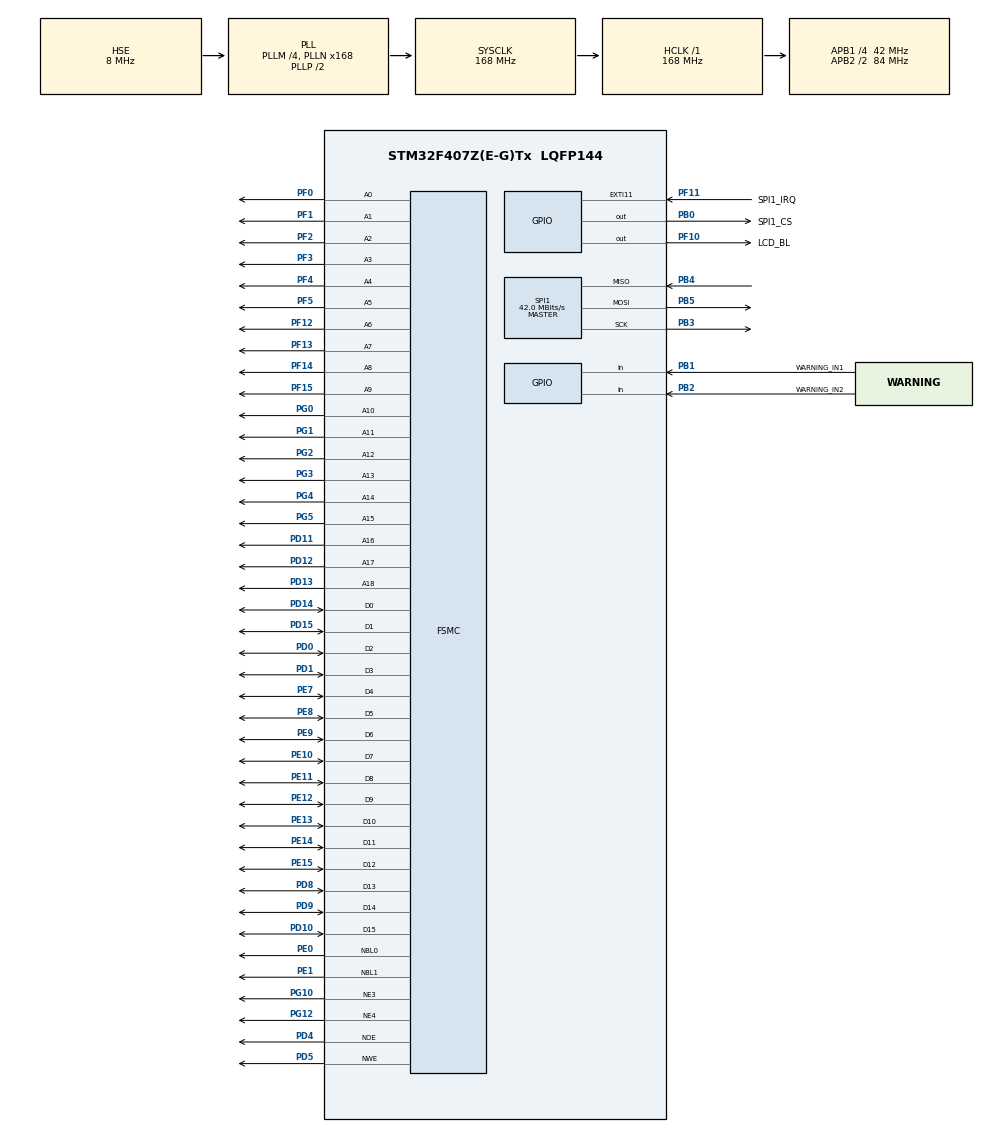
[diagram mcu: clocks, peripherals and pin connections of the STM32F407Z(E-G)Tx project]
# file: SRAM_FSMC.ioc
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Dma.Request0=SPI1_RX
Dma.Request1=SPI1_TX
Dma.SPI1_RX.0.Direction=DMA_PERIPH_TO_MEMORY
Dma.SPI1_RX.0.FIFOMode=DMA_FIFOMODE_DISABLE
Dma.SPI1_RX.0.Instance=DMA2_Stream0
Dma.SPI1_RX.0.MemDataAlignment=DMA_MDATAALIGN_HALFWORD
Dma.SPI1_RX.0.MemInc=DMA_MINC_ENABLE
Dma.SPI1_RX.0.Mode=DMA_NORMAL
Dma.SPI1_RX.0.PeriphDataAlignment=DMA_PDATAALIGN_HALFWORD
Dma.SPI1_RX.0.PeriphInc=DMA_PINC_DISABLE
Dma.SPI1_RX.0.Priority=DMA_PRIORITY_VERY_HIGH
Dma.SPI1_TX.1.Direction=DMA_MEMORY_TO_PERIPH
Dma.SPI1_TX.1.FIFOMode=DMA_FIFOMODE_DISABLE
Dma.SPI1_TX.1.Instance=DMA2_Stream3
Dma.SPI1_TX.1.MemDataAlignment=DMA_MDATAALIGN_HALFWORD
Dma.SPI1_TX.1.MemInc=DMA_MINC_ENABLE
Dma.SPI1_TX.1.Mode=DMA_NORMAL
Dma.SPI1_TX.1.PeriphDataAlignment=DMA_PDATAALIGN_HALFWORD
Dma.SPI1_TX.1.PeriphInc=DMA_PINC_DISABLE
Dma.SPI1_TX.1.Priority=DMA_PRIORITY_VERY_HIGH
FSMC.BusTurnAroundDuration2=15
FSMC.ExtendedMode1=FSMC_EXTENDED_MODE_ENABLE
FSMC.ExtendedMode2=FSMC_EXTENDED_MODE_ENABLE
FSMC.WriteOperation1=FSMC_WRITE_OPERATION_ENABLE
Mcu.Family=STM32F4
Mcu.Name=STM32F407Z(E-G)Tx
Mcu.Package=LQFP144
NVIC.DMA2_Stream0_IRQn=true\:0\:0\:false\:false\:true\:false\:true\:true
NVIC.DMA2_Stream3_IRQn=true\:0\:0\:false\:false\:true\:false\:true\:true
NVIC.EXTI15_10_IRQn=true\:0\:0\:false\:false\:true\:true\:true\:true
NVIC.PriorityGroup=NVIC_PRIORITYGROUP_4
NVIC.SPI1_IRQn=true\:0\:0\:false\:false\:true\:true\:true\:true
NVIC.TIM5_IRQn=true\:0\:0\:false\:false\:true\:true\:true\:true
PA13.Mode=Serial_Wire
PA13.Signal=SYS_JTMS-SWDIO
PA14.Mode=Serial_Wire
PA14.Signal=SYS_JTCK-SWCLK
PB0.GPIO_Label=SPI1_CS
PB0.GPIO_PuPd=GPIO_PULLUP
PB0.PinState=GPIO_PIN_SET
PB0.Signal=GPIO_Output
PB1.GPIO_Label=WARNING_IN1
PB1.Signal=GPIO_Input
PB2.GPIO_Label=WARNING_IN2
PB2.Signal=GPIO_Input
PB3.Mode=Full_Duplex_Master
PB3.Signal=SPI1_SCK
PB4.Mode=Full_Duplex_Master
PB4.Signal=SPI1_MISO
PB5.Mode=Full_Duplex_Master
PB5.Signal=SPI1_MOSI
PD0.GPIO_PuPd=GPIO_PULLDOWN
PD0.Signal=FSMC_D2_DA2
PD1.GPIO_PuPd=GPIO_PULLDOWN
PD1.Signal=FSMC_D3_DA3
PD10.GPIO_PuPd=GPIO_PULLDOWN
PD10.Signal=FSMC_D15_DA15
PD11.Signal=FSMC_A16_CLE
PD12.Signal=FSMC_A17_ALE
PD13.Signal=FSMC_A18
PD14.GPIO_PuPd=GPIO_PULLDOWN
PD14.Signal=FSMC_D0_DA0
PD15.GPIO_PuPd=GPIO_PULLDOWN
PD15.Signal=FSMC_D1_DA1
PD4.GPIO_PuPd=GPIO_PULLUP
PD4.Signal=FSMC_NOE
PD5.GPIO_PuPd=GPIO_PULLUP
PD5.Signal=FSMC_NWE
PD8.GPIO_PuPd=GPIO_PULLDOWN
PD8.Signal=FSMC_D13_DA13
PD9.GPIO_PuPd=GPIO_PULLDOWN
PD9.Signal=FSMC_D14_DA14
PE0.Signal=FSMC_NBL0
PE1.Signal=FSMC_NBL1
PE10.GPIO_PuPd=GPIO_PULLDOWN
PE10.Signal=FSMC_D7_DA7
PE11.GPIO_PuPd=GPIO_PULLDOWN
PE11.Signal=FSMC_D8_DA8
PE12.GPIO_PuPd=GPIO_PULLDOWN
PE12.Signal=FSMC_D9_DA9
PE13.GPIO_PuPd=GPIO_PULLDOWN
PE13.Signal=FSMC_D10_DA10
PE14.GPIO_PuPd=GPIO_PULLDOWN
PE14.Signal=FSMC_D11_DA11
PE15.GPIO_PuPd=GPIO_PULLDOWN
PE15.Signal=FSMC_D12_DA12
PE7.GPIO_PuPd=GPIO_PULLDOWN
PE7.Signal=FSMC_D4_DA4
PE8.GPIO_PuPd=GPIO_PULLDOWN
PE8.Signal=FSMC_D5_DA5
PE9.GPIO_PuPd=GPIO_PULLDOWN
PE9.Signal=FSMC_D6_DA6
PF0.Signal=FSMC_A0
PF1.Signal=FSMC_A1
PF10.GPIO_Label=LCD_BL
PF10.GPIO_PuPd=GPIO_PULLDOWN
PF10.Signal=GPIO_Output
PF11.GPIO_Label=SPI1_IRQ
PF11.GPIO_ModeDefaultEXTI=GPIO_MODE_IT_RISING_FALLING
PF11.GPIO_PuPd=GPIO_PULLUP
PF11.Signal=GPXTI11
PF12.Signal=FSMC_A6
PF13.Signal=FSMC_A7
PF14.Signal=FSMC_A8
PF15.Signal=FSMC_A9
PF2.Signal=FSMC_A2
PF3.Signal=FSMC_A3
PF4.Signal=FSMC_A4
PF5.Signal=FSMC_A5
PG0.Signal=FSMC_A10
PG1.Signal=FSMC_A11
PG10.Mode=NorPsramChipSelect3_1
PG10.Signal=FSMC_NE3
PG12.Mode=NorPsramChipSelect4_2
PG12.Signal=FSMC_NE4
PG2.Signal=FSMC_A12
PG3.Signal=FSMC_A13
PG4.Signal=FSMC_A14
PG5.Signal=FSMC_A15
PH0-OSC_IN.Mode=HSE-External-Oscillator
PH0-OSC_IN.Signal=RCC_OSC_IN
PH1-OSC_OUT.Mode=HSE-External-Oscillator
PH1-OSC_OUT.Signal=RCC_OSC_OUT
ProjectManager.HeapSize=0x200
ProjectManager.StackSize=0x400
ProjectManager.TargetToolchain=MDK-ARM V5
RCC.48MHZClocksFreq_Value=48000000
RCC.AHBFreq_Value=168000000
RCC.APB1CLKDivider=RCC_HCLK_DIV4
RCC.APB1Freq_Value=42000000
RCC.APB1TimFreq_Value=84000000
RCC.APB2CLKDivider=RCC_HCLK_DIV2
RCC.APB2Freq_Value=84000000
RCC.APB2TimFreq_Value=168000000
RCC.CortexFreq_Value=168000000
RCC.EnbaleCSS=true
RCC.HCLKFreq_Value=168000000
RCC.HSE_VALUE=8000000
RCC.HSI_VALUE=16000000
RCC.LSE_VALUE=32768
RCC.PLLM=4
RCC.PLLN=168
RCC.PLLQ=7
RCC.PLLSourceVirtual=RCC_PLLSOURCE_HSE
RCC.SYSCLKFreq_VALUE=168000000
RCC.SYSCLKSource=RCC_SYSCLKSOURCE_PLLCLK
RCC.VCOOutputFreq_Value=336000000
SH.FSMC_A0.0=FSMC_A0,19b-a1
SH.FSMC_A1.0=FSMC_A1,19b-a1
SH.FSMC_A10.0=FSMC_A10,19b-a1
SH.FSMC_A11.0=FSMC_A11,19b-a1
SH.FSMC_A12.0=FSMC_A12,A12_2
SH.FSMC_A12.1=FSMC_A12,19b-a1
SH.FSMC_A13.0=FSMC_A13,19b-a1
SH.FSMC_A14.0=FSMC_A14,19b-a1
SH.FSMC_A15.0=FSMC_A15,19b-a1
SH.FSMC_A16_CLE.0=FSMC_A16,19b-a1
SH.FSMC_A17_ALE.0=FSMC_A17,19b-a1
SH.FSMC_A18.0=FSMC_A18,19b-a1
SH.FSMC_A2.0=FSMC_A2,19b-a1
SH.FSMC_A3.0=FSMC_A3,19b-a1
SH.FSMC_A4.0=FSMC_A4,19b-a1
SH.FSMC_A5.0=FSMC_A5,19b-a1
SH.FSMC_A6.0=FSMC_A6,19b-a1
SH.FSMC_A7.0=FSMC_A7,19b-a1
SH.FSMC_A8.0=FSMC_A8,19b-a1
SH.FSMC_A9.0=FSMC_A9,19b-a1
SH.FSMC_D0_DA0.0=FSMC_D0,16b-d2
SH.FSMC_D0_DA0.1=FSMC_D0,16b-d1
SH.FSMC_D10_DA10.0=FSMC_D10,16b-d2
SH.FSMC_D10_DA10.1=FSMC_D10,16b-d1
SH.FSMC_D11_DA11.0=FSMC_D11,16b-d2
SH.FSMC_D11_DA11.1=FSMC_D11,16b-d1
SH.FSMC_D12_DA12.0=FSMC_D12,16b-d2
SH.FSMC_D12_DA12.1=FSMC_D12,16b-d1
SH.FSMC_D13_DA13.0=FSMC_D13,16b-d2
SH.FSMC_D13_DA13.1=FSMC_D13,16b-d1
SH.FSMC_D14_DA14.0=FSMC_D14,16b-d2
SH.FSMC_D14_DA14.1=FSMC_D14,16b-d1
SH.FSMC_D15_DA15.0=FSMC_D15,16b-d2
SH.FSMC_D15_DA15.1=FSMC_D15,16b-d1
SH.FSMC_D1_DA1.0=FSMC_D1,16b-d2
SH.FSMC_D1_DA1.1=FSMC_D1,16b-d1
SH.FSMC_D2_DA2.0=FSMC_D2,16b-d2
SH.FSMC_D2_DA2.1=FSMC_D2,16b-d1
SH.FSMC_D3_DA3.0=FSMC_D3,16b-d2
SH.FSMC_D3_DA3.1=FSMC_D3,16b-d1
SH.FSMC_D4_DA4.0=FSMC_D4,16b-d2
SH.FSMC_D4_DA4.1=FSMC_D4,16b-d1
SH.FSMC_D5_DA5.0=FSMC_D5,16b-d2
SH.FSMC_D5_DA5.1=FSMC_D5,16b-d1
SH.FSMC_D6_DA6.0=FSMC_D6,16b-d2
SH.FSMC_D6_DA6.1=FSMC_D6,16b-d1
SH.FSMC_D7_DA7.0=FSMC_D7,16b-d2
SH.FSMC_D7_DA7.1=FSMC_D7,16b-d1
SH.FSMC_D8_DA8.0=FSMC_D8,16b-d2
SH.FSMC_D8_DA8.1=FSMC_D8,16b-d1
SH.FSMC_D9_DA9.0=FSMC_D9,16b-d2
SH.FSMC_D9_DA9.1=FSMC_D9,16b-d1
SH.FSMC_NBL0.0=FSMC_NBL0,2ByteEnable1
SH.FSMC_NBL1.0=FSMC_NBL1,2ByteEnable1
SH.FSMC_NOE.0=FSMC_NOE,Lcd2
SH.FSMC_NOE.1=FSMC_NOE,Sram1
SH.FSMC_NWE.0=FSMC_NWE,Lcd2
SH.FSMC_NWE.1=FSMC_NWE,Sram1
SPI1.BaudRatePrescaler=SPI_BAUDRATEPRESCALER_2
SPI1.CalculateBaudRate=42.0 MBits/s
SPI1.Direction=SPI_DIRECTION_2LINES
SPI1.Mode=SPI_MODE_MASTER
SPI1.VirtualType=VM_MASTER
TIM5.Period=1
TIM5.Prescaler=8399
VP_TIM5_VS_ClockSourceINT.Mode=Internal
board=custom

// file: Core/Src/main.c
/* USER CODE BEGIN Header */
/**
  ******************************************************************************
  * @file           : main.c
  * @brief          : Main program body
  ******************************************************************************
  * @attention
  *
  * Copyright (c) 2025 STMicroelectronics.
  * All rights reserved.
  *
  * This software is licensed under terms that can be found in the LICENSE file
  * in the root directory of this software component.
  * If no LICENSE file comes with this software, it is provided AS-IS.
  *
  ******************************************************************************
  */
/* USER CODE END Header */
#include "main.h"
#include "dma.h"
#include "spi.h"
#include "tim.h"
#include "gpio.h"
#include "fsmc.h"

/* USER CODE BEGIN Includes */
#include "EventRecorder.h"
#include "hal_is62wv51216.h"
/* USER CODE END Includes */

void SystemClock_Config(void);

/* USER CODE BEGIN 0 */
u32 _eventRecordAll;

//******************* Примеры использования IS62WV51216 *****************************
// ссылку на объект управления драйвером микросхемы SRAM - IS62WV51216
// на случай, если надо отслеживать счетчики ошибок или доп. инфу.
IS62WV51216_s_obj* p_sram;
//------------------------------------------------------------------------------------
/* USER CODE END 0 */

int main(void)
{

  /* MCU Configuration--------------------------------------------------------*/

  /* Reset of all peripherals, Initializes the Flash interface and the Systick. */
  HAL_Init();

  /* Configure the system clock */
  SystemClock_Config();

  /* USER CODE BEGIN SysInit */
  EventRecorderInitialize(_eventRecordAll, 1);
  /* USER CODE END SysInit */

  /* Initialize all configured peripherals */
  MX_GPIO_Init();
  MX_DMA_Init();
  MX_FSMC_Init();
  MX_SPI1_Init();
  MX_TIM5_Init();
  /* USER CODE BEGIN 2 */
  //******************* Примеры использования IS62WV51216 *****************************
  IS62WV51216_Init(IS62WV51216_NUM_DRV_1, &hsram1, IS62WV51216_DMA_ON);
  p_sram = IS62WV51216_Get_Obj_Link();
  HAL_TIM_Base_Start_IT(&htim5);
  //------------------------------------------------------------------------------------
  /* USER CODE END 2 */

  /* Infinite loop */
  /* USER CODE BEGIN WHILE */
  while (1)
  {
    //******************* Примеры использования IS62WV51216 *****************************
//    cu8 size = 100;
//    u16 bf_tx[size];
//    u16 bf_rx[size];
    //------------------------------------------------------------------------------------
//    for(u16 i = 0, j = 0; i < size; i++, j += 500)
//      bf_tx[i] = j;
//
//    IS62WV51216_Rw_Data(0, 0, (u16*)&bf_tx, size, IS62WV51216_WRITE, IS62WV51216_SET_DMA_OFF);
//    IS62WV51216_Rw_Data(0, 0, (u16*)&bf_rx, size, IS62WV51216_READ, IS62WV51216_SET_DMA_OFF);
    //------------------------------------------------------------------------------------
//    for(u16 i = 0, j = 0; i < size; i++, j += 101)
//      bf_tx[i] = j;
//
//    IS62WV51216_Rw_Data(0, 0, (u16*)&bf_tx, size, IS62WV51216_WRITE, IS62WV51216_DMA_ON);
//    IS62WV51216_Rw_Data(0, 0, (u16*)&bf_rx, size, IS62WV51216_READ, IS62WV51216_DMA_ON);
    //------------------------------------------------------------------------------------
//    u8 hi_byte = 0, lo_byte = 0;
//    // чтение страшего и младшего байта
//    IS62WV51216_Rw_Byte(0, 99, &hi_byte, IS62WV51216_READ, IS62WV51216_HI_BYTE);  // 0xC1
//    IS62WV51216_Rw_Byte(0, 99, &lo_byte, IS62WV51216_READ, IS62WV51216_LO_BYTE);  // 0x5C
//    // запись страшего байта
//    hi_byte = 0x66, lo_byte = 0xDD;
//    IS62WV51216_Rw_Byte(0, 99, &hi_byte, IS62WV51216_WRITE, IS62WV51216_HI_BYTE);
//    hi_byte = 0;
//    IS62WV51216_Rw_Byte(0, 99, &hi_byte, IS62WV51216_READ, IS62WV51216_HI_BYTE);  // 0x66
//    // запись младшего байта
//    IS62WV51216_Rw_Byte(0, 99, &lo_byte, IS62WV51216_WRITE, IS62WV51216_LO_BYTE);
//    lo_byte = 0;
//    IS62WV51216_Rw_Byte(0, 99, &lo_byte, IS62WV51216_READ, IS62WV51216_LO_BYTE);  // 0xDD
    //------------------------------------------------------------------------------------
    IS62WV51216_Handler();
    //------------------------------------------------------------------------------------
    /* USER CODE END WHILE */

  }
}

void SystemClock_Config(void)
{
  RCC_OscInitTypeDef RCC_OscInitStruct = {0};
  RCC_ClkInitTypeDef RCC_ClkInitStruct = {0};

  /** Configure the main internal regulator output voltage
  */
  __HAL_RCC_PWR_CLK_ENABLE();
  __HAL_PWR_VOLTAGESCALING_CONFIG(PWR_REGULATOR_VOLTAGE_SCALE1);

  /** Initializes the RCC Oscillators according to the specified parameters
  * in the RCC_OscInitTypeDef structure.
  */
  RCC_OscInitStruct.OscillatorType = RCC_OSCILLATORTYPE_HSE;
  RCC_OscInitStruct.HSEState = RCC_HSE_ON;
  RCC_OscInitStruct.PLL.PLLState = RCC_PLL_ON;
  RCC_OscInitStruct.PLL.PLLSource = RCC_PLLSOURCE_HSE;
  RCC_OscInitStruct.PLL.PLLM = 4;
  RCC_OscInitStruct.PLL.PLLN = 168;
  RCC_OscInitStruct.PLL.PLLP = RCC_PLLP_DIV2;
  RCC_OscInitStruct.PLL.PLLQ = 7;
  if (HAL_RCC_OscConfig(&RCC_OscInitStruct) != HAL_OK)
  {
    Error_Handler();
  }

  /** Initializes the CPU, AHB and APB buses clocks
  */
  RCC_ClkInitStruct.ClockType = RCC_CLOCKTYPE_HCLK|RCC_CLOCKTYPE_SYSCLK
                              |RCC_CLOCKTYPE_PCLK1|RCC_CLOCKTYPE_PCLK2;
  RCC_ClkInitStruct.SYSCLKSource = RCC_SYSCLKSOURCE_PLLCLK;
  RCC_ClkInitStruct.AHBCLKDivider = RCC_SYSCLK_DIV1;
  RCC_ClkInitStruct.APB1CLKDivider = RCC_HCLK_DIV4;
  RCC_ClkInitStruct.APB2CLKDivider = RCC_HCLK_DIV2;

  if (HAL_RCC_ClockConfig(&RCC_ClkInitStruct, FLASH_LATENCY_5) != HAL_OK)
  {
    Error_Handler();
  }

  /** Enables the Clock Security System
  */
  HAL_RCC_EnableCSS();
}

void Error_Handler(void)
{
  __disable_irq();
  while (1)
  {
  }
}
